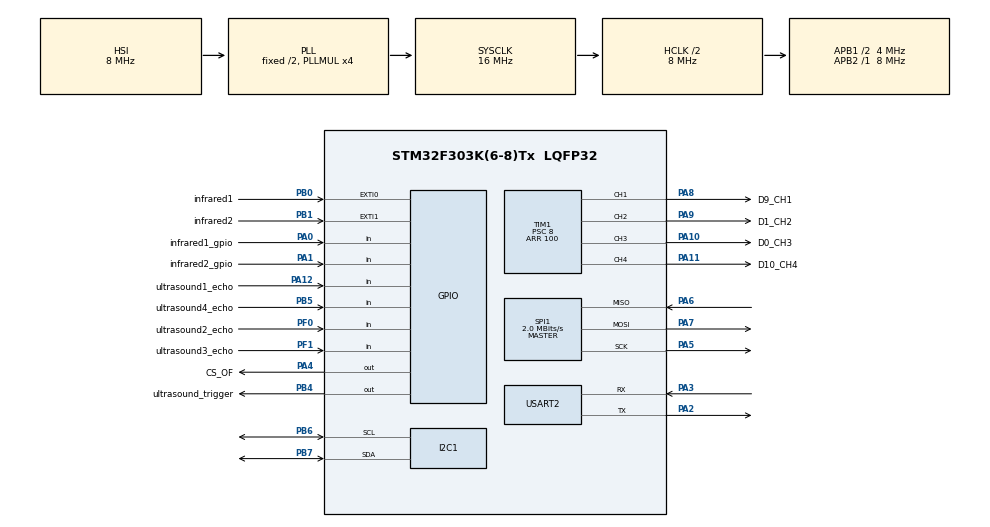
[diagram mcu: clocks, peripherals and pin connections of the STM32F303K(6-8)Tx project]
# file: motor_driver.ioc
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Mcu.Family=STM32F3
Mcu.Name=STM32F303K(6-8)Tx
Mcu.Package=LQFP32
NVIC.EXTI0_IRQn=true\:1\:0\:true\:false\:true\:true\:true
NVIC.EXTI1_IRQn=true\:1\:0\:true\:false\:true\:true\:true
NVIC.PriorityGroup=NVIC_PRIORITYGROUP_4
PA0.GPIO_Label=infrared1_gpio
PA0.Signal=GPIO_Input
PA1.GPIO_Label=infrared2_gpio
PA1.Signal=GPIO_Input
PA10.GPIO_Label=D0_CH3
PA10.Signal=S_TIM1_CH3
PA11.GPIO_Label=D10_CH4
PA11.Signal=S_TIM1_CH4
PA12.GPIO_Label=ultrasound1_echo
PA12.Signal=GPIO_Input
PA13.Signal=SYS_JTMS-SWDIO
PA14.Signal=SYS_JTCK-SWCLK
PA2.Mode=Asynchronous
PA2.Signal=USART2_TX
PA3.Mode=Asynchronous
PA3.Signal=USART2_RX
PA4.GPIO_Label=CS_OF
PA4.Signal=GPIO_Output
PA5.Mode=Full_Duplex_Master
PA5.Signal=SPI1_SCK
PA6.Mode=Full_Duplex_Master
PA6.Signal=SPI1_MISO
PA7.Mode=Full_Duplex_Master
PA7.Signal=SPI1_MOSI
PA8.GPIO_Label=D9_CH1
PA8.Signal=S_TIM1_CH1
PA9.GPIO_Label=D1_CH2
PA9.Signal=S_TIM1_CH2
PB0.GPIO_Label=infrared1
PB0.Signal=GPXTI0
PB1.GPIO_Label=infrared2
PB1.Signal=GPXTI1
PB4.GPIO_Label=ultrasound_trigger
PB4.Signal=GPIO_Output
PB5.GPIO_Label=ultrasound4_echo
PB5.Signal=GPIO_Input
PB6.Mode=I2C
PB6.Signal=I2C1_SCL
PB7.Mode=I2C
PB7.Signal=I2C1_SDA
PF0\ /\ OSC_IN.GPIO_Label=ultrasound2_echo
PF0\ /\ OSC_IN.Signal=GPIO_Input
PF1\ /\ OSC_OUT.GPIO_Label=ultrasound3_echo
PF1\ /\ OSC_OUT.Signal=GPIO_Input
ProjectManager.HeapSize=0x200
ProjectManager.StackSize=0x400
ProjectManager.TargetToolchain=SW4STM32
RCC.AHBCLKDivider=RCC_SYSCLK_DIV2
RCC.AHBFreq_Value=8000000
RCC.APB1CLKDivider=RCC_HCLK_DIV2
RCC.APB1Freq_Value=4000000
RCC.APB1TimFreq_Value=8000000
RCC.APB2Freq_Value=8000000
RCC.APB2TimFreq_Value=8000000
RCC.CortexFreq_Value=8000000
RCC.HCLKFreq_Value=8000000
RCC.HSE_VALUE=8000000
RCC.HSI_VALUE=8000000
RCC.PLLMUL=RCC_PLL_MUL4
RCC.SYSCLKFreq_VALUE=16000000
RCC.SYSCLKSourceVirtual=RCC_SYSCLKSOURCE_PLLCLK
SH.S_TIM1_CH1.0=TIM1_CH1,PWM Generation1 CH1
SH.S_TIM1_CH2.0=TIM1_CH2,PWM Generation2 CH2
SH.S_TIM1_CH3.0=TIM1_CH3,PWM Generation3 CH3
SH.S_TIM1_CH4.0=TIM1_CH4,PWM Generation4 CH4
SPI1.BaudRatePrescaler=SPI_BAUDRATEPRESCALER_4
SPI1.CLKPhase=SPI_PHASE_2EDGE
SPI1.CLKPolarity=SPI_POLARITY_HIGH
SPI1.CalculateBaudRate=2.0 MBits/s
SPI1.DataSize=SPI_DATASIZE_8BIT
SPI1.Direction=SPI_DIRECTION_2LINES
SPI1.Mode=SPI_MODE_MASTER
SPI1.VirtualType=VM_MASTER
TIM1.Channel-PWM\ Generation1\ CH1=TIM_CHANNEL_1
TIM1.Channel-PWM\ Generation2\ CH2=TIM_CHANNEL_2
TIM1.Channel-PWM\ Generation3\ CH3=TIM_CHANNEL_3
TIM1.Channel-PWM\ Generation4\ CH4=TIM_CHANNEL_4
TIM1.Period=100
TIM1.Prescaler=8
TIM2.Period=100
TIM2.Prescaler=16
USART2.VirtualMode-Asynchronous=VM_ASYNC
VP_TIM1_VS_ClockSourceINT.Mode=Internal
VP_TIM2_VS_ClockSourceINT.Mode=Internal
board=custom

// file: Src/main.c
/* USER CODE BEGIN Header */
/**
  ******************************************************************************
  * @file           : main.c
  * @brief          : Main program body
  ******************************************************************************
  * @attention
  *
  * <h2><center>&copy; Copyright (c) 2020 STMicroelectronics.
  * All rights reserved.</center></h2>
  *
  * This software component is licensed by ST under BSD 3-Clause license,
  * the "License"; You may not use this file except in compliance with the
  * License. You may obtain a copy of the License at:
  *                        opensource.org/licenses/BSD-3-Clause
  *
  ******************************************************************************
  */
/* USER CODE END Header */

#include "main.h"
#include "i2c.h"
#include "spi.h"
#include "tim.h"
#include "usart.h"
#include "gpio.h"

/* USER CODE BEGIN Includes */
#include "motor_driver.h"
/* USER CODE END Includes */

void SystemClock_Config(void);

int main(void)
{

  /* MCU Configuration--------------------------------------------------------*/

  /* Reset of all peripherals, Initializes the Flash interface and the Systick. */
  HAL_Init();

  /* Configure the system clock */
  SystemClock_Config();

  /* Initialize all configured peripherals */
  MX_GPIO_Init();
  MX_TIM1_Init();
  MX_USART2_UART_Init();
  MX_I2C1_Init();
  MX_SPI1_Init();
  MX_TIM2_Init();
  /* USER CODE BEGIN 2 */
  //  we have 4 pwm channels
  pwm_init();

  /* USER CODE END 2 */

  /* Infinite loop */
  while (1)
  {

    /* USER CODE BEGIN 3 */
//
    for(int i=0; i<100; i++){
        moveRightMotor(i);
        HAL_Delay(5);
    }

    for(int i=0; i<100; i++){
          moveRightMotor(100-i);
          HAL_Delay(5);
    }

    for(int i=0; i<100; i++){
          moveRightMotor(-1*i);
          HAL_Delay(5);
    }

    for(int i=0; i<100; i++){
          moveRightMotor(-1*(100-i));
          HAL_Delay(5);
    }

//    for(int i=100; i>-100; i--){
//        moveRightMotor(i);
//        HAL_Delay(5);
//    }
//
//    for(int i=-100; i<100; i++){
//        moveRightMotor(i);
//        HAL_Delay(5);
//    }

//    for (int i=0; i<100; i++){
//        analogWrite(1, i);
//        analogWrite(2, 100-i);
//        analogWrite(3, i);
//        analogWrite(4, 100-i);
//        HAL_Delay(10);
//    }
//
//    for (int i=0; i<100; i++){
////        htim1.Instance->CCR1 = i;
//          analogWrite(1, 100-i);
//          analogWrite(2, i);
//          analogWrite(3, 100-i);
//          analogWrite(4, i);
//          HAL_Delay(10);
//      }
  }
  /* USER CODE END 3 */
}

void SystemClock_Config(void)
{
  RCC_OscInitTypeDef RCC_OscInitStruct = {0};
  RCC_ClkInitTypeDef RCC_ClkInitStruct = {0};
  RCC_PeriphCLKInitTypeDef PeriphClkInit = {0};

  /** Initializes the CPU, AHB and APB busses clocks
  */
  RCC_OscInitStruct.OscillatorType = RCC_OSCILLATORTYPE_HSI;
  RCC_OscInitStruct.HSIState = RCC_HSI_ON;
  RCC_OscInitStruct.HSICalibrationValue = RCC_HSICALIBRATION_DEFAULT;
  RCC_OscInitStruct.PLL.PLLState = RCC_PLL_ON;
  RCC_OscInitStruct.PLL.PLLSource = RCC_PLLSOURCE_HSI;
  RCC_OscInitStruct.PLL.PLLMUL = RCC_PLL_MUL4;
  if (HAL_RCC_OscConfig(&RCC_OscInitStruct) != HAL_OK)
  {
    Error_Handler();
  }
  /** Initializes the CPU, AHB and APB busses clocks
  */
  RCC_ClkInitStruct.ClockType = RCC_CLOCKTYPE_HCLK|RCC_CLOCKTYPE_SYSCLK
                              |RCC_CLOCKTYPE_PCLK1|RCC_CLOCKTYPE_PCLK2;
  RCC_ClkInitStruct.SYSCLKSource = RCC_SYSCLKSOURCE_PLLCLK;
  RCC_ClkInitStruct.AHBCLKDivider = RCC_SYSCLK_DIV2;
  RCC_ClkInitStruct.APB1CLKDivider = RCC_HCLK_DIV2;
  RCC_ClkInitStruct.APB2CLKDivider = RCC_HCLK_DIV1;

  if (HAL_RCC_ClockConfig(&RCC_ClkInitStruct, FLASH_LATENCY_0) != HAL_OK)
  {
    Error_Handler();
  }
  PeriphClkInit.PeriphClockSelection = RCC_PERIPHCLK_I2C1|RCC_PERIPHCLK_TIM1;
  PeriphClkInit.I2c1ClockSelection = RCC_I2C1CLKSOURCE_HSI;
  PeriphClkInit.Tim1ClockSelection = RCC_TIM1CLK_HCLK;
  if (HAL_RCCEx_PeriphCLKConfig(&PeriphClkInit) != HAL_OK)
  {
    Error_Handler();
  }
}

void Error_Handler(void)
{
}

/************************ (C) COPYRIGHT STMicroelectronics *****END OF FILE****/
